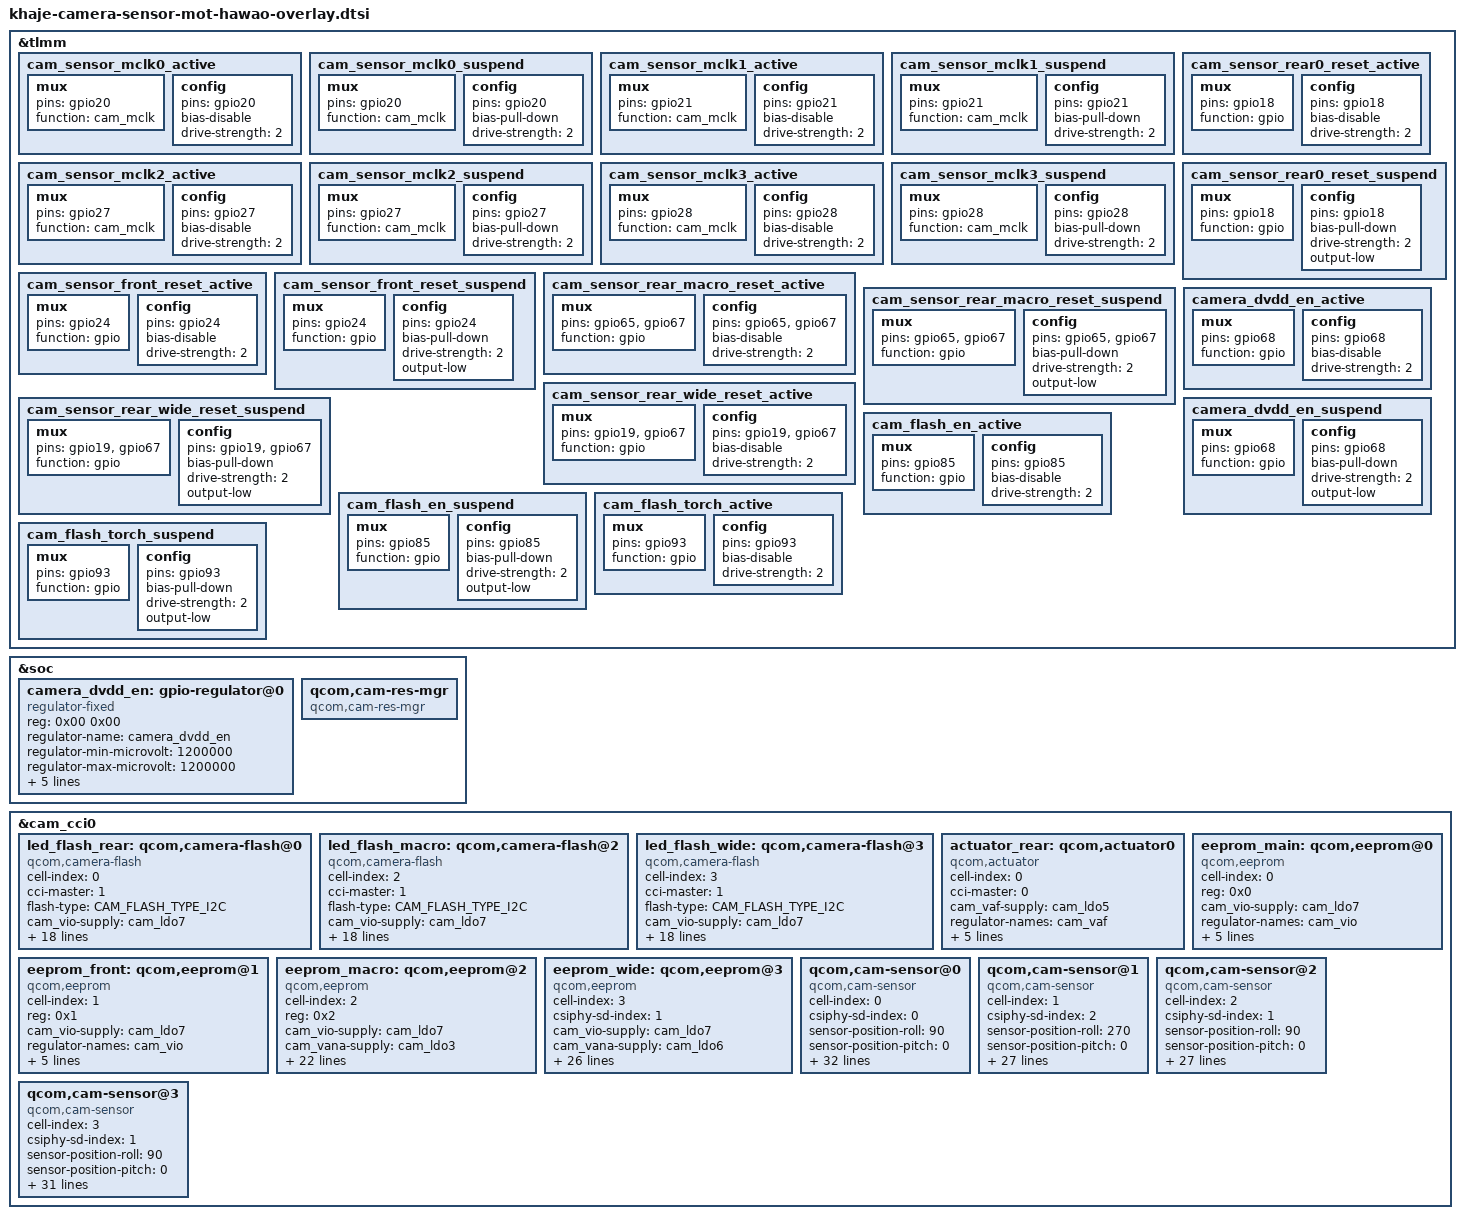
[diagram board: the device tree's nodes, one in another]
#include <dt-bindings/clock/qcom,gcc-khaje.h>
#include <dt-bindings/msm/msm-camera.h>

&tlmm {
	cam_sensor_mclk0_active: cam_sensor_mclk0_active {
		/* MCLK 0*/
		mux {
			pins = "gpio20";
			function = "cam_mclk";
		};

		config {
			pins = "gpio20";
			bias-disable;
			drive-strength = <2>;
		};
	};

	cam_sensor_mclk0_suspend: cam_sensor_mclk0_suspend {
		/* MCLK 0*/
		mux {
			pins = "gpio20";
			function = "cam_mclk";
		};

		config {
			pins = "gpio20";
			bias-pull-down;
			drive-strength = <2>;
		};
	};

	cam_sensor_mclk1_active: cam_sensor_mclk1_active {
		mux {
			pins = "gpio21";
			function = "cam_mclk";
		};

		config {
			pins = "gpio21";
			bias-disable; /* No PULL */
			drive-strength = <2>; /* 2 MA */
		};
	};

	cam_sensor_mclk1_suspend: cam_sensor_mclk1_suspend {
		mux {
			pins = "gpio21";
			function = "cam_mclk";
		};

		config {
			pins = "gpio21";
			bias-pull-down;
			drive-strength = <2>; /* 2 MA */
		};
	};

	cam_sensor_mclk2_active: cam_sensor_mclk2_active {
		mux {
			pins = "gpio27";
			function = "cam_mclk";
		};

		config {
			pins = "gpio27";
			bias-disable;
			drive-strength = <2>;
		};
	};

	cam_sensor_mclk2_suspend: cam_sensor_mclk2_suspend {
		mux {
			pins = "gpio27";
			function = "cam_mclk";
		};

		config {
			pins = "gpio27";
			bias-pull-down;
			drive-strength = <2>;
		};
	};

	cam_sensor_mclk3_active: cam_sensor_mclk3_active {
		/* MCLK 3*/
		mux {
			pins = "gpio28";
			function = "cam_mclk";
		};

		config {
			pins = "gpio28";
			bias-disable;
			drive-strength = <2>;
		};
	};

	cam_sensor_mclk3_suspend: cam_sensor_mclk3_suspend {
		/* MCLK 3*/
		mux {
			pins = "gpio28";
			function = "cam_mclk";
		};

		config {
			pins = "gpio28";
			bias-pull-down;
			drive-strength = <2>;
		};
	};

	cam_sensor_rear0_reset_active: cam_sensor_rear0_reset_active {
		mux {
			pins = "gpio18";
			function = "gpio";
		};

		config {
			pins = "gpio18";
			bias-disable; /* No PULL */
			drive-strength = <2>;
		};
	};

	cam_sensor_rear0_reset_suspend: cam_sensor_rear0_reset_suspend {
		mux {
			pins = "gpio18";
			function = "gpio";
		};

		config {
			pins = "gpio18";
			bias-pull-down; /* PULL DOWN */
			drive-strength = <2>;
			output-low;
		};
	};

	cam_sensor_front_reset_active: cam_sensor_front_reset_active {
		mux {
			pins = "gpio24";
			function = "gpio";
		};

		config {
			pins = "gpio24";
			bias-disable; /* No PULL */
			drive-strength = <2>;
		};
	};

	cam_sensor_front_reset_suspend: cam_sensor_front_reset_suspend {
		mux {
			pins = "gpio24";
			function = "gpio";
		};

		config {
			pins = "gpio24";
			bias-pull-down; /* PULL DOWN */
			drive-strength = <2>;
			output-low;
		};
	};

	cam_sensor_rear_macro_reset_active: cam_sensor_rear_macro_reset_active {
		mux {
			pins = "gpio65" ,"gpio67";
			function = "gpio";
		};

		config {
			pins = "gpio65" ,"gpio67";
			bias-disable; /* No PULL */
			drive-strength = <2>; /* 2 MA */
		};
	};

	cam_sensor_rear_macro_reset_suspend: cam_sensor_rear_macro_reset_suspend {
		mux {
			pins = "gpio65" ,"gpio67";
			function = "gpio";
		};

		config {
			pins = "gpio65" ,"gpio67";
			bias-pull-down; /* PULL DOWN */
			drive-strength = <2>; /* 2 MA */
			output-low;
		};
	};

	cam_sensor_rear_wide_reset_active: cam_sensor_rear_wide_reset_active {
		mux {
			pins = "gpio19" ,"gpio67";
			function = "gpio";
		};

		config {
			pins = "gpio19" ,"gpio67";
			bias-disable; /* No PULL */
			drive-strength = <2>; /* 2 MA */
		};
	};

	cam_sensor_rear_wide_reset_suspend: cam_sensor_rear_wide_reset_suspend {
		mux {
			pins = "gpio19" ,"gpio67";
			function = "gpio";
		};

		config {
			pins = "gpio19" ,"gpio67";
			bias-pull-down; /* PULL DOWN */
			drive-strength = <2>; /* 2 MA */
			output-low;
		};
	};

	camera_dvdd_en_active: camera_dvdd_en_active {
		/* VDIG */
		mux {
			pins = "gpio68";
			function = "gpio";
		};

		config {
			pins = "gpio68";
			bias-disable; /* No PULL */
			drive-strength = <2>; /* 2 MA */
		};
	};

	camera_dvdd_en_suspend: camera_dvdd_en_suspend {
		/* VDIG */
		mux {
			pins = "gpio68";
			function = "gpio";
		};

		config {
			pins = "gpio68";
			bias-pull-down; /* PULL DOWN */
			drive-strength = <2>; /* 2 MA */
			output-low;
		};
	};

	cam_flash_en_active: cam_flash_en_active {
		mux {
			pins = "gpio85";
			function = "gpio";
		};

		config {
			pins = "gpio85";
			bias-disable; /* No PULL */
			drive-strength = <2>; /* 2 MA */
		};
	};

	cam_flash_en_suspend: cam_flash_en_suspend {
		mux {
			pins = "gpio85";
			function = "gpio";
		};

		config {
			pins = "gpio85";
			bias-pull-down; /* PULL DOWN */
			drive-strength = <2>; /* 2 MA */
			output-low;
		};
	};

	cam_flash_torch_active: cam_flash_torch_active {
		mux {
			pins = "gpio93";
			function = "gpio";
		};

		config {
			pins = "gpio93";
			bias-disable; /* No PULL */
			drive-strength = <2>; /* 2 MA */
		};
	};

	cam_flash_torch_suspend: cam_flash_torch_suspend {
		mux {
			pins = "gpio93";
			function = "gpio";
		};

		config {
			pins = "gpio93";
			bias-pull-down; /* PULL DOWN */
			drive-strength = <2>; /* 2 MA */
			output-low;
		};
	};
};

&soc {
	camera_dvdd_en: gpio-regulator@0 {
		compatible = "regulator-fixed";
		reg = <0x00 0x00>;
		regulator-name = "camera_dvdd_en";
		regulator-min-microvolt = <1200000>;
		regulator-max-microvolt = <1200000>;
		regulator-enable-ramp-delay = <233>;
		enable-active-high;
		gpio = <&tlmm 68 0>;
		pinctrl-names = "default";
		pinctrl-0 = <&camera_dvdd_en_active>;
		vin-supply = <&S6A>;
	};

	qcom,cam-res-mgr {
		compatible = "qcom,cam-res-mgr";
		status = "ok";
	};
};

&cam_cci0 {
	led_flash_rear: qcom,camera-flash@0 {
		cell-index = <0>;
		compatible = "qcom,camera-flash";
		cci-master = <1>;
		flash-type = <CAM_FLASH_TYPE_I2C>;
		cam_vio-supply = <&cam_ldo7>;
		regulator-names = "cam_vio";
		rgltr-cntrl-support;
		rgltr-min-voltage = <1800000>;
		rgltr-max-voltage = <1800000>;
		rgltr-load-current = <3000>;
		gpio-no-mux = <0>;
		pinctrl-names = "cam_default","cam_suspend";
		pinctrl-0 = <&cam_flash_en_active &cam_flash_torch_active>;
		pinctrl-1 = <&cam_flash_en_suspend &cam_flash_torch_suspend>;
		gpios = <&tlmm 85 0>,
			<&tlmm 93 0>;
		gpio-custom1 = <0>;
		gpio-custom2 = <1>;
		gpio-req-tbl-num = <0 1>;
		gpio-req-tbl-flags = <0 0>;
		gpio-req-tbl-label = "SENSOR_CUSTOM_GPIO1",
				"SENSOR_CUSTOM_GPIO2";
		distinguish-flash-supplier = <0xc6 0x0c 0x0a>;
		status = "ok";
	};

	led_flash_macro: qcom,camera-flash@2 {
		cell-index = <2>;
		compatible = "qcom,camera-flash";
		cci-master = <1>;
		flash-type = <CAM_FLASH_TYPE_I2C>;
		cam_vio-supply = <&cam_ldo7>;
		regulator-names = "cam_vio";
		rgltr-cntrl-support;
		rgltr-min-voltage = <1800000>;
		rgltr-max-voltage = <1800000>;
		rgltr-load-current = <3000>;
		gpio-no-mux = <0>;
		pinctrl-names = "cam_default","cam_suspend";
		pinctrl-0 = <&cam_flash_en_active &cam_flash_torch_active>;
		pinctrl-1 = <&cam_flash_en_suspend &cam_flash_torch_suspend>;
		gpios = <&tlmm 85 0>,
			<&tlmm 93 0>;
		gpio-custom1 = <0>;
		gpio-custom2 = <1>;
		gpio-req-tbl-num = <0 1>;
		gpio-req-tbl-flags = <0 0>;
		gpio-req-tbl-label = "SENSOR_CUSTOM_GPIO1",
				"SENSOR_CUSTOM_GPIO2";
		distinguish-flash-supplier = <0xc6 0x0c 0x0a>;
		status = "ok";
	};

	led_flash_wide: qcom,camera-flash@3 {
		cell-index = <3>;
		compatible = "qcom,camera-flash";
		cci-master = <1>;
		flash-type = <CAM_FLASH_TYPE_I2C>;
		cam_vio-supply = <&cam_ldo7>;
		regulator-names = "cam_vio";
		rgltr-cntrl-support;
		rgltr-min-voltage = <1800000>;
		rgltr-max-voltage = <1800000>;
		rgltr-load-current = <3000>;
		gpio-no-mux = <0>;
		pinctrl-names = "cam_default","cam_suspend";
		pinctrl-0 = <&cam_flash_en_active &cam_flash_torch_active>;
		pinctrl-1 = <&cam_flash_en_suspend &cam_flash_torch_suspend>;
		gpios = <&tlmm 85 0>,
			<&tlmm 93 0>;
		gpio-custom1 = <0>;
		gpio-custom2 = <1>;
		gpio-req-tbl-num = <0 1>;
		gpio-req-tbl-flags = <0 0>;
		gpio-req-tbl-label = "SENSOR_CUSTOM_GPIO1",
				"SENSOR_CUSTOM_GPIO2";
		distinguish-flash-supplier = <0xc6 0x0c 0x0a>;
		status = "ok";
	};
	actuator_rear: qcom,actuator0 {
		cell-index = <0>;
		compatible = "qcom,actuator";
		cci-master = <0>;
		cam_vaf-supply = <&cam_ldo5>;
		regulator-names = "cam_vaf";
		rgltr-cntrl-support;
		rgltr-min-voltage = <2800000>;
		rgltr-max-voltage = <2800000>;
		rgltr-load-current = <2800000>;
		multi-user-support;
		status = "ok";
	};

	eeprom_main: qcom,eeprom@0 {
		cell-index = <0>;
		reg = <0x0>;
		compatible = "qcom,eeprom";
		cam_vio-supply = <&cam_ldo7>;
		regulator-names = "cam_vio";
		rgltr-cntrl-support;
		rgltr-min-voltage = <1800000>;
		rgltr-max-voltage = <1800000>;
		rgltr-load-current = <3000>;
		cci-master = <0>;
		status = "ok";
	};

	eeprom_front: qcom,eeprom@1 {
		cell-index = <1>;
		reg = <0x1>;
		compatible = "qcom,eeprom";
		cam_vio-supply = <&cam_ldo7>;
		regulator-names = "cam_vio";
		rgltr-cntrl-support;
		rgltr-min-voltage = <1800000>;
		rgltr-max-voltage = <1800000>;
		rgltr-load-current = <3000>;
		cci-master = <1>;
		status = "ok";
	};

	eeprom_macro: qcom,eeprom@2 {
		cell-index = <2>;
		reg = <0x2>;
		compatible = "qcom,eeprom";
		cam_vio-supply = <&cam_ldo7>;
		cam_vana-supply = <&cam_ldo3>;
		cam_clk-supply = <&gcc_camss_top_gdsc>;
		regulator-names = "cam_vio", "cam_vana", "cam_clk";
		rgltr-cntrl-support;
		rgltr-min-voltage = <1800000 2800000 0>;
		rgltr-max-voltage = <1800000 2800000 0>;
		rgltr-load-current = <120000 80000 0>;
		gpio-no-mux = <0>;
		pinctrl-names = "cam_default", "cam_suspend";
		pinctrl-0 = <&cam_sensor_mclk3_active
				&cam_sensor_rear_macro_reset_active>;
		pinctrl-1 = <&cam_sensor_mclk3_suspend
				&cam_sensor_rear_macro_reset_suspend>;
		gpios = <&tlmm 28 0>,
			<&tlmm 65 0>,
			<&tlmm 67 0>;
		gpio-reset = <1>;
		gpio-custom1 = <2>;//sel low for macro,high for wide
		gpio-req-tbl-num = <0 1 2>;
		gpio-req-tbl-flags = <1 0 0>;
		gpio-req-tbl-label = "CAMIF_MCLK3",
					"CAM_RESET3",
					"CAM_MIPI_SEL";
		cci-master = <0>;
		status = "ok";
		clocks = <&gcc GCC_CAMSS_MCLK3_CLK>;
		clock-names = "cam_clk";
		clock-cntl-level = "turbo";
		clock-rates = <24000000>;
	};

	eeprom_wide:qcom,eeprom@3 {
		cell-index = <3>;
		compatible = "qcom,eeprom";
		csiphy-sd-index = <1>;
		cam_vio-supply = <&cam_ldo7>;
		cam_vana-supply = <&cam_ldo6>;
		cam_vdig-supply = <&camera_dvdd_en>;
		cam_clk-supply = <&gcc_camss_top_gdsc>;
		regulator-names = "cam_vio", "cam_vana", "cam_vdig",
			"cam_clk";
		rgltr-cntrl-support;
		pwm-switch;
		rgltr-min-voltage = <1800000 2800000 1200000 0>;
		rgltr-max-voltage = <1800000 2800000 1200000 0>;
		rgltr-load-current = <120000 80000 1200000 0>;
		gpio-no-mux = <0>;
		pinctrl-names = "cam_default", "cam_suspend";
		pinctrl-0 = <&cam_sensor_mclk1_active
				&cam_sensor_rear_wide_reset_active>;
		pinctrl-1 = <&cam_sensor_mclk1_suspend
				&cam_sensor_rear_wide_reset_suspend>;
		gpios = <&tlmm 21 0>,
			<&tlmm 19 0>,
			<&tlmm 67 0>;
		gpio-reset = <1>;
		gpio-custom1 = <2>;
		gpio-req-tbl-num = <0 1 2>;
		gpio-req-tbl-flags = <1 0 0>;
		gpio-req-tbl-label = "CAMIF_MCLK1",
					"CAM_RESET1",
					"CAM_SWICH_SEL";
		sensor-mode = <0>;
		cci-master = <1>;
		status = "ok";
		clocks = <&gcc GCC_CAMSS_MCLK1_CLK>;
		clock-names = "cam_clk";
		clock-cntl-level = "turbo";
		clock-rates = <24000000>;
	};

	 /* main : JN1*/
	qcom,cam-sensor@0 {
		cell-index = <0>;
		compatible = "qcom,cam-sensor";
		csiphy-sd-index = <0>;
		sensor-position-roll = <90>;
		sensor-position-pitch = <0>;
		sensor-position-yaw = <180>;
		eeprom-src = <&eeprom_main>;
		led-flash-src = <&led_flash_rear>;
		actuator-src = <&actuator_rear>;
		cam_vio-supply = <&cam_ldo7>;
		cam_vana-supply = <&cam_ldo4>;
		cam_vdig-supply = <&cam_ldo2>;
		cam_clk-supply = <&gcc_camss_top_gdsc>;
		regulator-names ="cam_vio", "cam_vana", "cam_vdig",
			"cam_clk","cam_vaf";
		rgltr-cntrl-support;
		pwm-switch;
		rgltr-min-voltage = <1800000 2800000 1050000 0 2800000>;
		rgltr-max-voltage = <1800000 2800000 1050000 0 2800000>;
		rgltr-load-current = <1800000 2800000 1050000 0 100000>;
		gpio-no-mux = <0>;
		pinctrl-names = "cam_default", "cam_suspend";
		pinctrl-0 = <&cam_sensor_mclk0_active
				&cam_sensor_rear0_reset_active>;
		pinctrl-1 = <&cam_sensor_mclk0_suspend
				&cam_sensor_rear0_reset_suspend>;
		gpios = <&tlmm 20 0>,
			<&tlmm 18 0>;
		gpio-reset = <1>;
		gpio-req-tbl-num = <0 1>;
		gpio-req-tbl-flags = <1 0>;
		gpio-req-tbl-label = "CAMIF_MCLK0",
					"CAM_RESET0";
		cci-master = <0>;
		status = "ok";
		clocks = <&gcc GCC_CAMSS_MCLK0_CLK>;
		clock-names = "cam_clk";
		clock-cntl-level = "turbo";
		clock-rates = <24000000>;
	};

	/*front*/
	 qcom,cam-sensor@1 {
		cell-index = <1>;
		compatible = "qcom,cam-sensor";
		csiphy-sd-index = <2>;
		sensor-position-roll = <270>;
		sensor-position-pitch = <0>;
		sensor-position-yaw = <180>;
		eeprom-src = <&eeprom_front>;
		cam_vio-supply = <&cam_ldo7>;
		cam_vana-supply = <&cam_ldo3>;
		cam_vdig-supply = <&cam_ldo1>;
		cam_clk-supply = <&gcc_camss_top_gdsc>;
		regulator-names = "cam_vio", "cam_vana", "cam_vdig",
			"cam_clk";
		rgltr-cntrl-support;
		pwm-switch;
		rgltr-min-voltage = <1800000 2800000 1100000 0>;
		rgltr-max-voltage = <1800000 2800000 1100000 0>;
		rgltr-load-current = <120000 80000 1100000 0>;
		gpio-no-mux = <0>;
		pinctrl-names = "cam_default", "cam_suspend";
		pinctrl-0 = <&cam_sensor_mclk2_active
					&cam_sensor_front_reset_active>;
		pinctrl-1 = <&cam_sensor_mclk2_suspend
					&cam_sensor_front_reset_suspend>;
		gpios = <&tlmm 27 0>,
				<&tlmm 24 0>;
		gpio-reset = <1>;
		gpio-req-tbl-num = <0 1 >;
		gpio-req-tbl-flags = <1 0 >;
		gpio-req-tbl-label = "CAMIF_MCLK2",
					"CAM_RESET2";
		cci-master = <1>;
		status = "ok";
		clocks = <&gcc GCC_CAMSS_MCLK2_CLK>;
		clock-names = "cam_clk";
		clock-cntl-level = "turbo";
		clock-rates = <24000000>;
	};

	/* macro : gc02m1 */
	qcom,cam-sensor@2 {
		cell-index = <2>;
		compatible = "qcom,cam-sensor";
		csiphy-sd-index = <1>;
		sensor-position-roll = <90>;
		sensor-position-pitch = <0>;
		sensor-position-yaw = <180>;
		eeprom-src = <&eeprom_macro>;
		led-flash-src = <&led_flash_macro>;
		cam_vio-supply = <&cam_ldo7>;
		cam_vana-supply = <&cam_ldo3>;
		cam_clk-supply = <&gcc_camss_top_gdsc>;
		regulator-names = "cam_vio", "cam_vana", "cam_clk";
		rgltr-cntrl-support;
		rgltr-min-voltage = <1800000 2800000 0>;
		rgltr-max-voltage = <1800000 2800000 0>;
		rgltr-load-current = <120000 80000 0>;
		gpio-no-mux = <0>;
		pinctrl-names = "cam_default", "cam_suspend";
		pinctrl-0 = <&cam_sensor_mclk3_active
				&cam_sensor_rear_macro_reset_active>;
		pinctrl-1 = <&cam_sensor_mclk3_suspend
				&cam_sensor_rear_macro_reset_suspend>;
		gpios = <&tlmm 28 0>,
			<&tlmm 65 0>,
			<&tlmm 67 0>;
		gpio-reset = <1>;
		gpio-custom1 = <2>;//sel low for macro,high for wide
		gpio-req-tbl-num = <0 1 2>;
		gpio-req-tbl-flags = <1 0 0>;
		gpio-req-tbl-label = "CAMIF_MCLK3",
					"CAM_RESET3",
					"CAM_MIPI_SEL";
		cci-master = <0>;
		status = "ok";
		clocks = <&gcc GCC_CAMSS_MCLK3_CLK>;
		clock-names = "cam_clk";
		clock-cntl-level = "turbo";
		clock-rates = <24000000>;
	};

	/*Rear Aux*/
	qcom,cam-sensor@3 {
		cell-index = <3>;
		compatible = "qcom,cam-sensor";
		csiphy-sd-index = <1>;
		sensor-position-roll = <90>;
		sensor-position-pitch = <0>;
		sensor-position-yaw = <180>;
		eeprom-src = <&eeprom_wide>;
		led-flash-src = <&led_flash_wide>;
		cam_vio-supply = <&cam_ldo7>;
		cam_vana-supply = <&cam_ldo6>;
		cam_vdig-supply = <&camera_dvdd_en>;
		cam_clk-supply = <&gcc_camss_top_gdsc>;
		regulator-names = "cam_vio", "cam_vana", "cam_vdig",
			"cam_clk";
		rgltr-cntrl-support;
		pwm-switch;
		rgltr-min-voltage = <1800000 2800000 1200000 0>;
		rgltr-max-voltage = <1800000 2800000 1200000 0>;
		rgltr-load-current = <120000 80000 1200000 0>;
		gpio-no-mux = <0>;
		pinctrl-names = "cam_default", "cam_suspend";
		pinctrl-0 = <&cam_sensor_mclk1_active
				&cam_sensor_rear_wide_reset_active>;
		pinctrl-1 = <&cam_sensor_mclk1_suspend
				&cam_sensor_rear_wide_reset_suspend>;
		gpios = <&tlmm 21 0>,
			<&tlmm 19 0>,
			<&tlmm 67 0>;
		gpio-reset = <1>;
		gpio-custom1 = <2>;
		gpio-req-tbl-num = <0 1 2>;
		gpio-req-tbl-flags = <1 0 0>;
		gpio-req-tbl-label = "CAMIF_MCLK1",
					"CAM_RESET1",
					"CAM_SWICH_SEL";
		sensor-mode = <0>;
		cci-master = <1>;
		status = "ok";
		clocks = <&gcc GCC_CAMSS_MCLK1_CLK>;
		clock-names = "cam_clk";
		clock-cntl-level = "turbo";
		clock-rates = <24000000>;
	};
};
